# CEC1712H_B2_SX register map
Vendor: Microchip
Registers are 32-bit, read-write, reset 0x0 unless marked. A register's access mark holds for its fields unless they carry their own. Addresses are absolute, and some are shared; only a register's first bit layout is shown; [hi:lo] are bit positions.

## WDT
0x40000400 LOAD 16-bit reset 0xFFFF
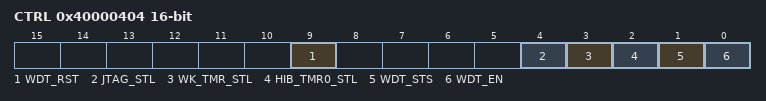
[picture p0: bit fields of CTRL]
0x40000404 CTRL 16-bit
  [9] WDT_RST — If the WDT_RESET bit is set and the watch dog timer expires, the Watch dog module will generate interrupt and clear the WDT_RESET to 0b.
  [4] JTAG_STL — This bit enables the WDT Stall function if JTAG or SWD debug functions are active. 1=The WDT is stalled while either JTAG or SWD is active. 0=The WDT is not affected by the JTAG debug interface.
  [3] WK_TMR_STL — This bit enables the WDT Stall function if the Week Timer is active. 1=The WDT is stalled while the Week Timer is active. 0=The WDT is not affected by the Week Timer.
  [2] HIB_TMR0_STL — This bit enables the WDT Stall function if the Hibernation Timer 0 is active. 1=The WDT is stalled while the Hibernation Timer 0 is active. 0=The WDT is not affected by Hibernation Timer 0.
  [1] WDT_STS — WDT_STATUS is set by hardware if the last reset of the device was caused by an underflow of the WDT. This bit must be cleared by the EC firmware writing a '1' to this bit. Writing a '0' to this bit has no effect.
  [0] WDT_EN — WDT Block enabled
0x40000408 KICK 8-bit wo
0x4000040C CNT 16-bit ro reset 0xFFFF
0x40000410 STS 8-bit
  [0] WDT_EV_IRQ — WDT_EVENT_IRQ : This bit indicates the status of interrupt from Watch dog module.
0x40000414 IEN 8-bit
  [0] WDT_INTEN — WDT_Int_Enable: This is the interrupt enables bit for WDT_INT interrupt. 1= WDT_INT Interrupt Enable 0= WDT_INT Interrupt Disabled

## TIMER16_0
0x40000C00 CNT
0x40000C04 PRLD
0x40000C08 STS
  [0] EVT_INT — This is the interrupt status that fires when the timer reaches its limit. This is the interrupt status that fires when the timer reaches its limit. This may be level or a self clearing signal cycle pulse, based on the AUTO_RESTART bit in the Timer. Control Register. If the timer is set to automatically restart, it will provide a pulse, otherwise a level is provided.(R/WC)
0x40000C0C IEN
  [0] EN — This is the interrupt enable for the status EVENT_INTERRUPT bit in the Timer Status Register.
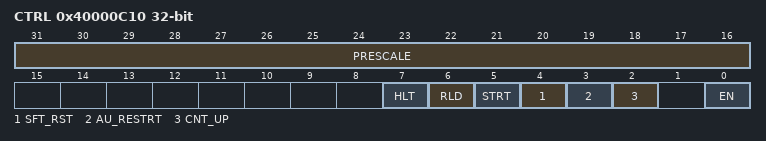
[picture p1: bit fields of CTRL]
0x40000C10 CTRL
  [31:16] PRESCALE — This is used to divide down the system clock through clock enables to lower the power consumption of the block and allow slow timers. Updating this value during operation may result in erroneous clock enable pulses until the clock divider restarts. The number of clocks per clock enable pulse is (Value + 1); a setting of 0 runs at the full clock speed, while a setting of 1 runs at half speed.
  [7] HLT — This is a halt bit. This will halt the timer as long as it is active. Once the halt is inactive, the timer will start from where it left off. 1=Timer is halted. It stops counting. The clock divider will also be reset. 0=Timer runs normally.
  [6] RLD — This bit reloads the counter without interrupting it operation. This will not function if the timer has already completed (when the START bit in this register is '0'). This is used to periodically prevent the timer from firing when an event occurs. Usage while the timer is off may result in erroneous behaviour.
  [5] STRT — This bit triggers the timer counter. The counter will operate until it hits its terminating condition. This will clear this bit. It should be noted that when operating in restart mode, there is no terminating condition for the counter, so this bit will never clear. Clearing this bit will halt the timer counter.
  [4] SFT_RST — This is a soft reset. This is self clearing 1 cycle after it is written. Firmware does not need to wait before reconfiguring the Basic Timer following soft reset.
  [3] AU_RESTRT — This will select the action taken upon completing a count. 1=The counter will automatically restart the count, using the contents of the Timer Preload Register to load the Timer Count Register. The interrupt will be set in edge mode. 0=The counter will simply enter a done state and wait for further control inputs. The interrupt will be set in level mode.
  [2] CNT_UP — This selects the counter direction. When the counter in incrementing the counter will saturate and trigger the event when it reaches all F's. When the counter is decrementing the counter will saturate when it reaches 0h. 1=The counter will increment; 0=The counter will decrement
  [0] EN — This enables the block for operation. 1=This block will function normally; 0=This block will gate its clock and go into its lowest power state
